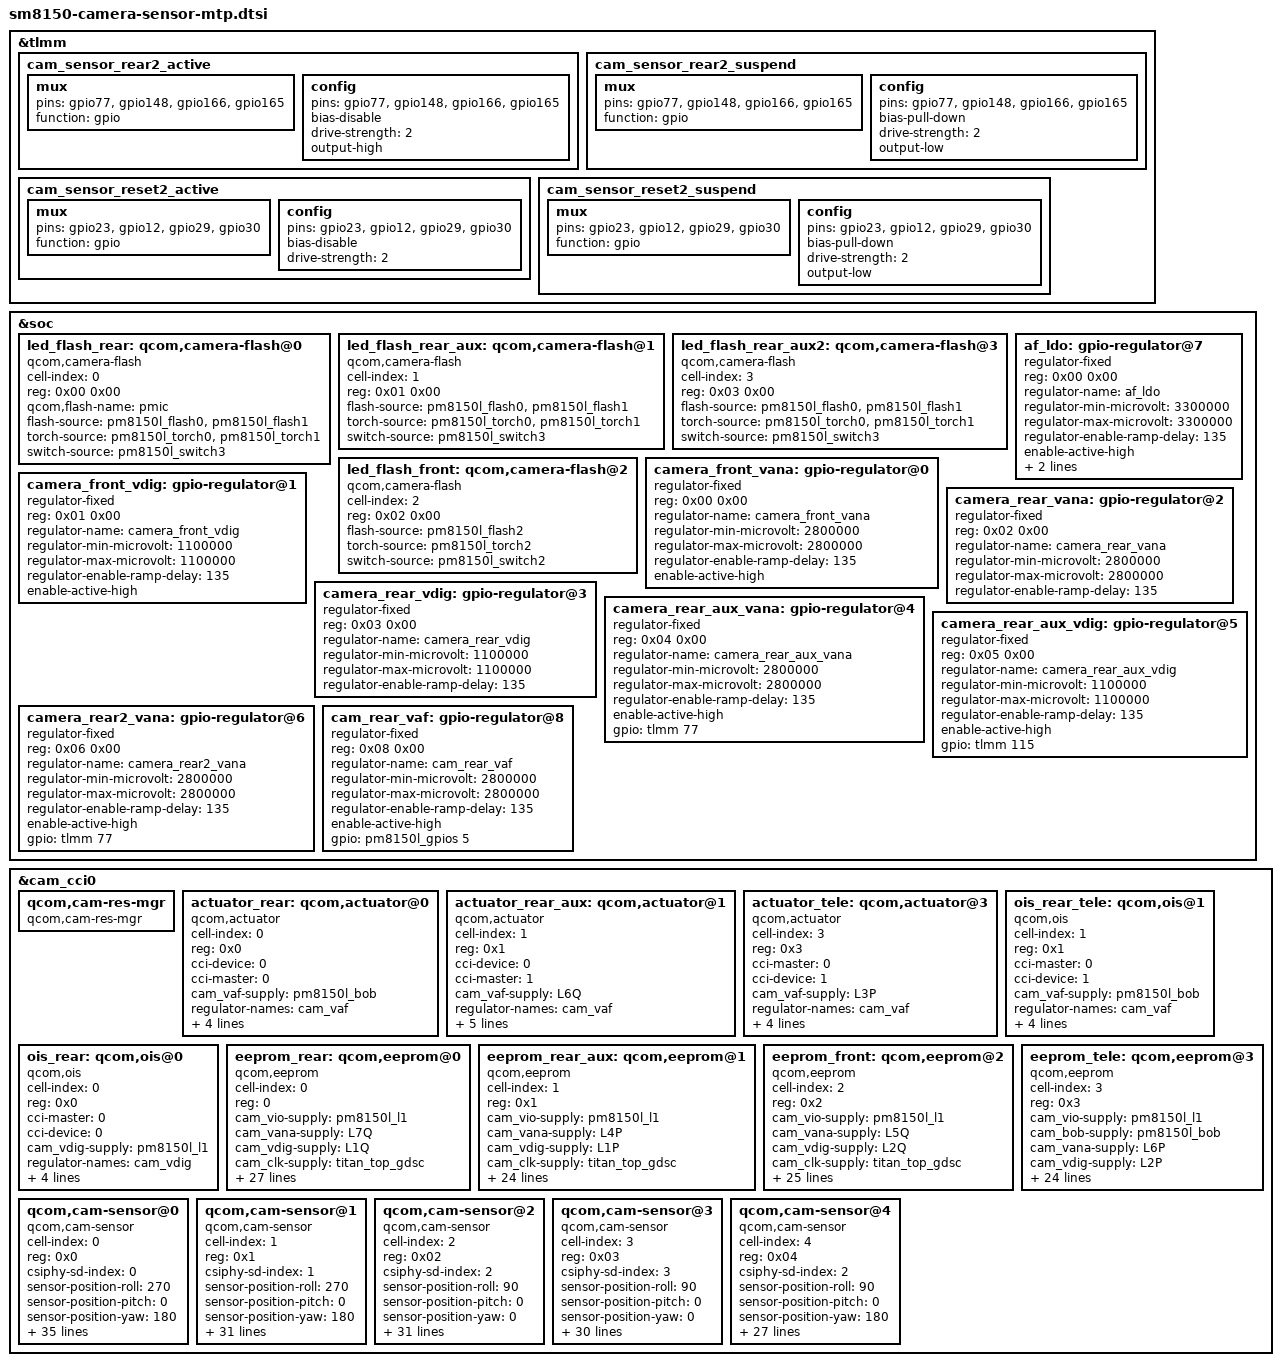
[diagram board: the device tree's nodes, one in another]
/*
 * Copyright (c) 2018-2019, The Linux Foundation. All rights reserved.
 *
 * This program is free software; you can redistribute it and/or modify
 * it under the terms of the GNU General Public License version 2 and
 * only version 2 as published by the Free Software Foundation.
 *
 * This program is distributed in the hope that it will be useful,
 * but WITHOUT ANY WARRANTY; without even the implied warranty of
 * MERCHANTABILITY or FITNESS FOR A PARTICULAR PURPOSE.  See the
 * GNU General Public License for more details.
 */

/* #ifdef VENDOR_EDIT */
&tlmm {
	cam_sensor_rear2_active: cam_sensor_rear2_active {
		/* RESET REAR2 */
		mux {
			pins = "gpio77", "gpio148", "gpio166", "gpio165";
			function = "gpio";
		};

		config {
			pins = "gpio77", "gpio148", "gpio166", "gpio165";
			bias-disable; /* No PULL */
			drive-strength = <2>; /* 2 MA */
			output-high;
		};
	};

	cam_sensor_rear2_suspend: cam_sensor_rear2_suspend {
		/* RESET REAR2 */
		mux {
			pins = "gpio77", "gpio148", "gpio166", "gpio165";
			function = "gpio";
		};

		config {
			pins = "gpio77", "gpio148", "gpio166", "gpio165";
			bias-pull-down; /* PULL DOWN */
			drive-strength = <2>; /* 2 MA */
			output-low;
		};
	};
	cam_sensor_reset2_active: cam_sensor_reset2_active {
		/* RESET REAR2 */
		mux {
			pins = "gpio23","gpio12","gpio29","gpio30";
			function = "gpio";
		};

		config {
			pins = "gpio23","gpio12","gpio29","gpio30";
			bias-disable; /* No PULL */
			drive-strength = <2>; /* 2 MA */
		};
	};

	cam_sensor_reset2_suspend: cam_sensor_reset2_suspend {
		/* RESET REAR2 */
		mux {
			pins = "gpio23","gpio12","gpio29","gpio30";
			function = "gpio";
		};

		config {
			pins = "gpio23","gpio12","gpio29","gpio30";
			bias-pull-down; /* PULL DOWN */
			drive-strength = <2>; /* 2 MA */
			output-low;
		};
	};

};
/* #endif */

&soc {
	#address-cells = <1>;
	#size-cells = <1>;

	led_flash_rear: qcom,camera-flash@0 {
		cell-index = <0>;
		reg = <0x00 0x00>;
		compatible = "qcom,camera-flash";
		qcom,flash-name = "pmic";
		flash-source = <&pm8150l_flash0 &pm8150l_flash1>;
		torch-source = <&pm8150l_torch0 &pm8150l_torch1>;
		switch-source = <&pm8150l_switch3>;
		status = "ok";
	};

	/* #ifdef VENDOR_EDIT */

	led_flash_rear_aux: qcom,camera-flash@1 {
		cell-index = <1>;
		reg = <0x01 0x00>;
		compatible = "qcom,camera-flash";
		flash-source = <&pm8150l_flash0 &pm8150l_flash1>;
		torch-source = <&pm8150l_torch0 &pm8150l_torch1>;
		switch-source = <&pm8150l_switch3>;
		status = "ok";
	};

	led_flash_rear_aux2: qcom,camera-flash@3 {
		cell-index = <3>;
		reg = <0x03 0x00>;
		compatible = "qcom,camera-flash";
		flash-source = <&pm8150l_flash0 &pm8150l_flash1>;
		torch-source = <&pm8150l_torch0 &pm8150l_torch1>;
		switch-source = <&pm8150l_switch3>;
		status = "ok";
	};

	/*#endif*/

	af_ldo: gpio-regulator@7 {
		compatible = "regulator-fixed";
		reg = <0x00 0x00>;
		regulator-name = "af_ldo";
		regulator-min-microvolt = <3300000>;
		regulator-max-microvolt = <3300000>;
		regulator-enable-ramp-delay = <135>;
		enable-active-high;
		gpio = <&tlmm 11 0>;
		pinctrl-names = "default";
		//pinctrl-0 = <&cam_sensor_dvdd_en>;
		vin-supply = <&pm8150l_l1>;
	};

	led_flash_front: qcom,camera-flash@2 {
		cell-index = <2>;
		reg = <0x02 0x00>;
		compatible = "qcom,camera-flash";
		/*#ifndef VENDOR_EDIT*/
		/*
		wled-flash-support;
		flash-source = <&wled_flash>;
		torch-source = <&wled_torch>;
		switch-source = <&wled_switch>;
		*/
		/*#else*/
		flash-source = <&pm8150l_flash2>;
		torch-source = <&pm8150l_torch2>;
		switch-source = <&pm8150l_switch2>;
		/*#endif*/
		status = "ok";
	};

	/* #ifdef VENDOR_EDIT */
	/*
	led_flash_iris: qcom,camera-flash@3 {
		cell-index = <3>;
		reg = <0x03 0x00>;
		compatible = "qcom,camera-flash";
		flash-source = <&pm8150l_flash1>;
		torch-source = <&pm8150l_torch1>;
		switch-source = <&pm8150l_switch0>;
		status = "ok";
	};
	*/
	/*#endif*/

	/*#ifdef VENDOR_EDIT*/
	camera_front_vana: gpio-regulator@0 {
		compatible = "regulator-fixed";
		reg = <0x00 0x00>;
		regulator-name = "camera_front_vana";
		regulator-min-microvolt = <2800000>;
		regulator-max-microvolt = <2800000>;
		regulator-enable-ramp-delay = <135>;
		enable-active-high;
		//gpio = <&pm8150b_gpios 12 0>;
		//pinctrl-names = "default";
		//pinctrl-0 = <&cam_front_vana_default>;
		//vin-supply = <&pm8150l_bob>;
	};

	camera_front_vdig: gpio-regulator@1 {
		compatible = "regulator-fixed";
		reg = <0x01 0x00>;
		regulator-name = "camera_front_vdig";
		regulator-min-microvolt = <1100000>;
		regulator-max-microvolt = <1100000>;
		regulator-enable-ramp-delay = <135>;
		enable-active-high;
		//gpio = <&pm8150b_gpios 10 0>;
		//pinctrl-names = "default";
		//pinctrl-0 = <&cam_front_vdig_default>;
		//vin-supply = <&pm8150l_s8>;
	};

	camera_rear_vana: gpio-regulator@2 {
		compatible = "regulator-fixed";
		reg = <0x02 0x00>;
		regulator-name = "camera_rear_vana";
		regulator-min-microvolt = <2800000>;
		regulator-max-microvolt = <2800000>;
		regulator-enable-ramp-delay = <135>;
		//enable-active-high;
		//gpio = <&pm8150l_gpios 4 0>;
		//pinctrl-names = "default";
		//pinctrl-0 = <&cam_rear_vana_default>;
		//vin-supply = <&pm8150l_bob>;
	};

	camera_rear_vdig: gpio-regulator@3 {
		compatible = "regulator-fixed";
		reg = <0x03 0x00>;
		regulator-name = "camera_rear_vdig";
		regulator-min-microvolt = <1100000>;
		regulator-max-microvolt = <1100000>;
		regulator-enable-ramp-delay = <135>;
		//enable-active-high;
		//gpio = <&pm8150l_gpios 1 0>;
		//pinctrl-names = "default";
		//pinctrl-0 = <&cam_rear_vdig_default>;
		//vin-supply = <&pm8150l_s8>;
	};

	camera_rear_aux_vana: gpio-regulator@4 {
		compatible = "regulator-fixed";
		reg = <0x04 0x00>;
		regulator-name = "camera_rear_aux_vana";
		regulator-min-microvolt = <2800000>;
		regulator-max-microvolt = <2800000>;
		regulator-enable-ramp-delay = <135>;
		enable-active-high;
		gpio = <&tlmm 77 0>;
		//pinctrl-names = "default";
		//pinctrl-0 = <&cam_rear_aux_vana_default>;
		//vin-supply = <&pm8150l_bob>;
	};

	camera_rear_aux_vdig: gpio-regulator@5 {
		compatible = "regulator-fixed";
		reg = <0x05 0x00>;
		regulator-name = "camera_rear_aux_vdig";
		regulator-min-microvolt = <1100000>;
		regulator-max-microvolt = <1100000>;
		regulator-enable-ramp-delay = <135>;
		enable-active-high;
		gpio = <&tlmm 115 0>;
		//pinctrl-names = "default";
		//pinctrl-0 = <&cam_rear_aux_vdig_default>;
		//vin-supply = <&pm8150l_s8>;
	};
	/*#endif*/

        /* #ifdef VENDOR_EDIT */
	camera_rear2_vana: gpio-regulator@6 {
		compatible = "regulator-fixed";
		reg = <0x06 0x00>;
		regulator-name = "camera_rear2_vana";
		regulator-min-microvolt = <2800000>;
		regulator-max-microvolt = <2800000>;
		regulator-enable-ramp-delay = <135>;
		enable-active-high;
		gpio = <&tlmm 77 0>;
		//pinctrl-names = "active", "suspend";
		//pinctrl-0 = <&cam_sensor_rear2_active>;
		//pinctrl-1 = <&cam_sensor_rear2_suspend>;
		//vin-supply = <&pm8150l_bob>;
	};

	cam_rear_vaf: gpio-regulator@8 {
		compatible = "regulator-fixed";
		reg = <0x08 0x00>;
		regulator-name = "cam_rear_vaf";
		regulator-min-microvolt = <2800000>;
		regulator-max-microvolt = <2800000>;
		regulator-enable-ramp-delay = <135>;
		enable-active-high;
		gpio = <&pm8150l_gpios 5 0>;
		//pinctrl-names = "default";
		//pinctrl-0 = <&cam_sensor_dvdd_en>;
		//vin-supply = <&pm8150l_l1>;
	};
	/* #endif */
};

&cam_cci0 {
	#address-cells = <1>;
	#size-cells = <0>;

	qcom,cam-res-mgr {
		compatible = "qcom,cam-res-mgr";
		status = "ok";
	};
	/*
	actuator_rear: qcom,actuator@0 {
		cell-index = <0>;
		reg = <0x0>;
		compatible = "qcom,actuator";
		cci-master = <0>;
		cam_vaf-supply = <&pm8009_s2>;
		regulator-names = "cam_vaf";
		rgltr-cntrl-support;
		rgltr-min-voltage = <2856000>;
		rgltr-max-voltage = <2856000>;
		rgltr-load-current = <0>;
	};

	actuator_rear_aux: qcom,actuator@1 {
		cell-index = <1>;
		reg = <0x1>;
		compatible = "qcom,actuator";
		cci-master = <1>;
		cam_vaf-supply = <&pm8009_s2>;
		regulator-names = "cam_vaf";
		rgltr-cntrl-support;
		rgltr-min-voltage = <2856000>;
		rgltr-max-voltage = <2856000>;
		rgltr-load-current = <0>;
	};

	actuator_front: qcom,actuator@2 {
		cell-index = <2>;
		reg = <0x2>;
		compatible = "qcom,actuator";
		cci-master = <1>;
		cam_vaf-supply = <&pm8009_s2>;
		regulator-names = "cam_vaf";
		rgltr-cntrl-support;
		rgltr-min-voltage = <2856000>;
		rgltr-max-voltage = <2856000>;
		rgltr-load-current = <0>;
	};

	actuator_rear_aux: qcom,actuator@1 {
		cell-index = <1>;
		reg = <0x1>;
		compatible = "qcom,actuator";
		cci-device = <0>;
		cci-master = <0>;
		cam_vaf-supply = <&pm8150l_bob>;
		regulator-names = "cam_vaf";
		rgltr-cntrl-support;
		rgltr-min-voltage = <3300000>;
		rgltr-max-voltage = <3300000>;
		rgltr-load-current = <0>;
		gpio-no-mux = <0>;
		pinctrl-names = "cam_default", "cam_suspend";
		pinctrl-0 = <&cam_sensor_rear_1_vaf_active>;
		pinctrl-1 = <&cam_sensor_rear_1_vaf_suspend>;
		gpios = <&tlmm 35 0>;
		gpio-vaf = <0>;
		gpio-req-tbl-num = <0>;
		gpio-req-tbl-flags = <0>;
		gpio-req-tbl-label = "CAM_VAF_1";
	};
	*/
	actuator_rear: qcom,actuator@0 {
		cell-index = <0>;
		reg = <0x0>;
		compatible = "qcom,actuator";
		cci-device = <0>;
		cci-master = <0>;
		cam_vaf-supply = <&pm8150l_bob>;
		regulator-names = "cam_vaf";
		rgltr-cntrl-support;
		rgltr-min-voltage = <3300000>;
		rgltr-max-voltage = <3300000>;
		rgltr-load-current = <0>;
		/*
		gpio-no-mux = <0>;
		pinctrl-names = "cam_default", "cam_suspend";
		pinctrl-0 = <&cam_rear_vaf_active>;
		pinctrl-1 = <&cam_rear_vaf_suspend>;
		gpios = <&pm8150l_gpios 5 0>;
		gpio-vaf = <0>;
		gpio-req-tbl-num = <0>;
		gpio-req-tbl-flags = <0>;
		gpio-req-tbl-label = "CAM_VAF_0";
		*/
	};

	actuator_rear_aux: qcom,actuator@1 {
		cell-index = <1>;
		reg = <0x1>;
		compatible = "qcom,actuator";
		cci-device = <0>;
		cci-master = <1>;
		cam_vaf-supply = <&L6Q>;
		regulator-names = "cam_vaf";
		rgltr-cntrl-support;
		rgltr-min-voltage = <2800000>;
		rgltr-max-voltage = <2800000>;
		rgltr-load-current = <0>;
		gpio-no-mux = <0>;
		//pinctrl-names = "cam_default", "cam_suspend";
		//pinctrl-0 = <&cam_sensor_rear_1_vaf_active>;
		//pinctrl-1 = <&cam_sensor_rear_1_vaf_suspend>;
		/* #ifdef VENDOR_EDIT */
		//gpios = <&tlmm 11 0>;
		//gpio-vaf = <0>;
		//gpio-req-tbl-num = <0>;
		//gpio-req-tbl-flags = <0>;
		//gpio-req-tbl-label = "CAM_VAF_1";
		/* #endif */
	};

	/* #ifdef VENDOR_EDIT */
	actuator_tele: qcom,actuator@3 {
		cell-index = <3>;
		reg = <0x3>;
		compatible = "qcom,actuator";
		cci-master = <0>;
		cci-device = <1>;
		cam_vaf-supply = <&L3P>;
		regulator-names = "cam_vaf";
		rgltr-cntrl-support;
		rgltr-min-voltage = <2800000>;
		rgltr-max-voltage = <2800000>;
		rgltr-load-current = <0>;
		status = "ok";
	};

	ois_rear_tele: qcom,ois@1 {
		cell-index = <1>;
		reg = <0x1>;
		compatible = "qcom,ois";
		cci-master = <0>;
		cci-device = <1>;
		cam_vaf-supply = <&pm8150l_bob>;
		regulator-names = "cam_vaf";
		rgltr-cntrl-support;
		rgltr-min-voltage = <3300000>;
		rgltr-max-voltage = <3300000>;
		rgltr-load-current = <0>;
		status = "ok";
	};
	/* #endif */

	ois_rear: qcom,ois@0 {
		cell-index = <0>;
		reg = <0x0>;
		compatible = "qcom,ois";
		cci-master = <0>;
		cci-device = <0>;
		cam_vdig-supply = <&pm8150l_l1>;
		regulator-names = "cam_vdig";
		rgltr-cntrl-support;
		rgltr-min-voltage = <1800000>;
		rgltr-max-voltage = <1800000>;
		rgltr-load-current = <0>;
		status = "ok";
	};

	/*#ifdef VENDOR_EDIT*/
	/*remark by hongbo.dai@camera*/
	eeprom_rear: qcom,eeprom@0 {
		cell-index = <0>;
		reg = <0>;
		compatible = "qcom,eeprom";
		cam_vio-supply = <&pm8150l_l1>;
		//cam_bob-supply = <&pm8150l_bob>;
		cam_vana-supply = <&L7Q>;
		cam_vdig-supply = <&L1Q>;
		cam_clk-supply = <&titan_top_gdsc>;
		cam_vaf-supply = <&L3Q>;
		cam_v_custom1-supply = <&L4Q>;
		regulator-names = "cam_vio", "cam_vana", "cam_vdig",
			"cam_clk", "cam_vaf","cam_v_custom1";
		rgltr-cntrl-support;
		pwm-switch;
		rgltr-min-voltage = <0 2900000 1100000 0 2800000 1800000>;
		rgltr-max-voltage = <0 2900000 1100000 0 2800000 1800000>;
		rgltr-load-current = <0 80000 800000 0 80000 300000>;
		gpio-no-mux = <0>;
		pinctrl-names = "cam_default", "cam_suspend";
		pinctrl-0 = <&cam_sensor_mclk0_active
				&cam_rear_reset_active>;
		pinctrl-1 = <&cam_sensor_mclk0_suspend
				&cam_rear_reset_suspend>;
		gpios = <&tlmm 13 0>,
			<&pm8150_gpios 1 0>;
		gpio-reset = <1>;
		gpio-req-tbl-num = <0 1>;
		gpio-req-tbl-flags = <1 0>;
		gpio-req-tbl-label = "CAMIF_MCLK3",
					"CAM_RESET0";
		sensor-mode = <0>;
		cci-master = <0>;
		status = "ok";
		clocks = <&clock_camcc CAM_CC_MCLK0_CLK>;
		clock-names = "cam_clk";
		clock-cntl-level = "turbo";
		clock-rates = <19200000>;
	};

	eeprom_rear_aux: qcom,eeprom@1 {
		cell-index = <1>;
		reg = <0x1>;
		compatible = "qcom,eeprom";
		cam_vio-supply = <&pm8150l_l1>;
		cam_vana-supply = <&L4P>;
		cam_vdig-supply = <&L1P>;
		cam_clk-supply = <&titan_top_gdsc>;
		cam_bob-supply = <&pm8150l_bob>;
		regulator-names = "cam_vio", "cam_vana", "cam_vdig",
			"cam_clk", "cam_bob";
		rgltr-cntrl-support;
		pwm-switch;
		rgltr-min-voltage = <0 2800000 1100000 0 3008000>;
		rgltr-max-voltage = <0 2800000 1100000 0 4000000>;
		rgltr-load-current = <0 80000 60000 0 2000000>;
		gpio-no-mux = <0>;
		pinctrl-names = "cam_default", "cam_suspend";
		pinctrl-0 = <&cam_sensor_mclk1_active
				 &cam_sensor_active_rear_aux>;
		pinctrl-1 = <&cam_sensor_mclk1_suspend
				 &cam_sensor_suspend_rear_aux>;
		gpios = <&tlmm 14 0>,
			<&tlmm 30 0>;
		gpio-reset = <1>;
		gpio-req-tbl-num = <0 1>;
		gpio-req-tbl-flags = <1 0>;
		gpio-req-tbl-label = "CAMIF_MCLK1",
					"CAM_RESET1";
		sensor-mode = <0>;
		cci-device = <0>;
		cci-master = <1>;
		status = "ok";
		clocks = <&clock_camcc CAM_CC_MCLK1_CLK>;
		clock-names = "cam_clk";
		clock-cntl-level = "turbo";
		clock-rates = <19200000>;
	};

	/* #ifdef VENDOR_EDIT */
	eeprom_front: qcom,eeprom@2 {
		cell-index = <2>;
		reg = <0x2>;
		compatible = "qcom,eeprom";
		cam_vio-supply = <&pm8150l_l1>;
		cam_vana-supply = <&L5Q>;
		cam_vdig-supply = <&L2Q>;
		cam_clk-supply = <&titan_top_gdsc>;
		regulator-names = "cam_vio", "cam_vana", "cam_vdig", "cam_clk";
		rgltr-cntrl-support;
		pwm-switch;
		rgltr-min-voltage = <1800000 2800000 1050000 0 >;
		rgltr-max-voltage = <1800000 2800000 1050000 0 >;
		rgltr-load-current = <80000 50000 50000 0 >;
		gpio-no-mux = <0>;
		pinctrl-names = "cam_default", "cam_suspend","cam_reset";
		pinctrl-0 = <&cam_sensor_mclk2_active
					&cam_sensor_reset2_active>;
		pinctrl-1 = <&cam_sensor_mclk2_suspend
					&cam_sensor_reset2_suspend>;
		gpios = <&tlmm 15 0>,
				<&tlmm 12 0>,
				<&tlmm 29 0>;
		gpio-reset = <1>;
		gpio-custom1 = <2>;
		gpio-req-tbl-num = <0 1 2>;
		gpio-req-tbl-flags = <1 0 0>;
		gpio-req-tbl-label = "CAMIF_MCLK_2",
								"CAM_RESET2",
								"CAM_FRONT_EN";
		sensor-mode = <0>;
		cci-device = <1>;
		cci-master = <1>;
		status = "ok";
		clocks = <&clock_camcc CAM_CC_MCLK2_CLK>;
		clock-names = "cam_clk";
		clock-cntl-level = "turbo";
		clock-rates = <24000000>;
	};

	eeprom_tele: qcom,eeprom@3 {
		cell-index = <3>;
		reg = <0x3>;
		compatible = "qcom,eeprom";
		cam_vio-supply = <&pm8150l_l1>;
		cam_bob-supply = <&pm8150l_bob>;
		cam_vana-supply = <&L6P>;
		cam_vdig-supply = <&L2P>;
		cam_clk-supply = <&titan_top_gdsc>;
		regulator-names = "cam_vio", "cam_vana", "cam_clk", "cam_bob","cam_vdig";
		rgltr-cntrl-support;
		pwm-switch;
		rgltr-min-voltage = <0 2800000 0 3008000 1050000>;
		rgltr-max-voltage = <0 2800000 0 4000000 1050000>;
		rgltr-load-current = <0 80000 0 2000000 80000>;
		gpio-no-mux = <0>;
		pinctrl-names = "cam_default", "cam_suspend","cam_reset";
		pinctrl-0 = <&cam_sensor_mclk3_active
				 &cam_rear_aux2_reset_active>;
		pinctrl-1 = <&cam_sensor_mclk3_suspend
				 &cam_rear_aux2_reset_suspend>;
		gpios = <&tlmm 16 0>,
			<&tlmm 23 0>;
		gpio-reset = <1>;
		gpio-req-tbl-num = <0 1>;
		gpio-req-tbl-flags = <1 0>;
		gpio-req-tbl-label = "CAMIF_MCLK3",
					"CAM_RESET_3";
		sensor-mode = <0>;
		cci-device = <1>;
		cci-master = <0>;
		status = "ok";
		clocks = <&clock_camcc CAM_CC_MCLK3_CLK>;
		clock-names = "cam_clk";
		clock-cntl-level = "turbo";
		clock-rates = <19200000>;
	};
	/* #endif */

/*
	eeprom_front: qcom,eeprom@2 {
		cell-index = <2>;
		reg = <0x2>;
		compatible = "qcom,eeprom";
		cam_vio-supply = <&pm8150l_l1>;
		cam_vana-supply = <&pm8009_l6>;
		cam_vdig-supply = <&pm8009_l2>;
		cam_clk-supply = <&titan_top_gdsc>;
		cam_vaf-supply = <&pm8009_s2>;
		regulator-names = "cam_vio", "cam_vana", "cam_vdig",
			"cam_clk", "cam_vaf";
		rgltr-cntrl-support;
		rgltr-min-voltage = <0 2856000 1200000 0 2856000>;
		rgltr-max-voltage = <0 2856000 1200000 0 2856000>;
		rgltr-load-current = <0 80000 1200000 0 0>;
		gpio-no-mux = <0>;
		pinctrl-names = "cam_default", "cam_suspend";
		pinctrl-0 = <&cam_sensor_mclk2_active
				 &cam_sensor_active_front>;
		pinctrl-1 = <&cam_sensor_mclk2_suspend
				 &cam_sensor_suspend_front>;
		gpios = <&tlmm 15 0>,
			<&tlmm 12 0>;
		gpio-reset = <1>;
		gpio-req-tbl-num = <0 1>;
		gpio-req-tbl-flags = <1 0>;
		gpio-req-tbl-label = "CAMIF_MCLK2",
					"CAM_RESET2";
		sensor-position = <1>;
		sensor-mode = <0>;
		cci-master = <1>;
		status = "ok";
		clocks = <&clock_camcc CAM_CC_MCLK2_CLK>;
		clock-names = "cam_clk";
		clock-cntl-level = "turbo";
		clock-rates = <24000000>;
	};

	qcom,cam-sensor@0 {
		cell-index = <0>;
		compatible = "qcom,cam-sensor";
		reg = <0x0>;
		csiphy-sd-index = <0>;
		sensor-position-roll = <90>;
		sensor-position-pitch = <0>;
		sensor-position-yaw = <180>;
		led-flash-src = <&led_flash_rear>;
		actuator-src = <&actuator_rear>;
		ois-src = <&ois_rear>;
		eeprom-src = <&eeprom_rear>;
		cam_vio-supply = <&pm8150l_l1>;
		cam_bob-supply = <&pm8150l_bob>;
		cam_vana-supply = <&pm8009_l5>;
		cam_vdig-supply = <&pm8009_l2>;
		cam_clk-supply = <&titan_top_gdsc>;
		regulator-names = "cam_vio", "cam_vana", "cam_vdig",
			"cam_clk", "cam_bob";
		rgltr-cntrl-support;
		pwm-switch;
		rgltr-min-voltage = <0 2800000 1200000 0 3008000>;
		rgltr-max-voltage = <0 2800000 1200000 0 4000000>;
		rgltr-load-current = <0 80000 1200000 0 2000000>;
		gpio-no-mux = <0>;
		pinctrl-names = "cam_default", "cam_suspend";
		pinctrl-0 = <&cam_sensor_mclk0_active
				&cam_sensor_active_rear>;
		pinctrl-1 = <&cam_sensor_mclk0_suspend
				&cam_sensor_suspend_rear>;
		gpios = <&tlmm 13 0>,
			<&tlmm 78 0>;
		gpio-reset = <1>;
		gpio-req-tbl-num = <0 1>;
		gpio-req-tbl-flags = <1 0>;
		gpio-req-tbl-label = "CAMIF_MCLK0",
					"CAM_RESET0";
		sensor-mode = <0>;
		cci-master = <0>;
		status = "ok";
		clocks = <&clock_camcc CAM_CC_MCLK0_CLK>;
		clock-names = "cam_clk";
		clock-cntl-level = "turbo";
		clock-rates = <24000000>;
	};
	*/

	qcom,cam-sensor@0 {
		cell-index = <0>;
		compatible = "qcom,cam-sensor";
		reg = <0x0>;
		csiphy-sd-index = <0>;
		sensor-position-roll = <270>;
		sensor-position-pitch = <0>;
		sensor-position-yaw = <180>;
		led-flash-src = <&led_flash_rear>;
		actuator-src = <&actuator_rear>;
		ois-src = <&ois_rear>;
		eeprom-src = <&eeprom_rear>;
		cam_vio-supply = <&pm8150l_l1>;
		//cam_bob-supply = <&pm8150l_bob>;
		cam_vana-supply = <&L7Q>;
		cam_vdig-supply = <&L1Q>;
		cam_clk-supply = <&titan_top_gdsc>;
		cam_vaf-supply = <&L3Q>;
		cam_v_custom1-supply = <&L4Q>;
		regulator-names = "cam_vio", "cam_vana", "cam_vdig",
			"cam_clk", "cam_vaf","cam_v_custom1";
		rgltr-cntrl-support;
		pwm-switch;
		rgltr-min-voltage = <0 2900000 1100000 0 2800000 1800000>;
		rgltr-max-voltage = <0 2900000 1100000 0 2800000 1800000>;
		rgltr-load-current = <0 80000 800000 0 80000 300000>;
		gpio-no-mux = <0>;
		pinctrl-names = "cam_default", "cam_suspend";
		pinctrl-0 = <&cam_sensor_mclk0_active
				&cam_rear_reset_active>;
		pinctrl-1 = <&cam_sensor_mclk0_suspend
				&cam_rear_reset_suspend>;
		gpios = <&tlmm 13 0>,
			<&pm8150_gpios 1 0>;
		gpio-reset = <1>;
		gpio-req-tbl-num = <0 1>;
		gpio-req-tbl-flags = <1 0>;
		gpio-req-tbl-label = "CAMIF_MCLK3",
					"CAM_RESET0";
		sensor-mode = <0>;
		cci-master = <0>;
		status = "ok";
		clocks = <&clock_camcc CAM_CC_MCLK0_CLK>;
		clock-names = "cam_clk";
		clock-cntl-level = "turbo";
		clock-rates = <19200000>;
	};

	qcom,cam-sensor@1 {
		cell-index = <1>;
		compatible = "qcom,cam-sensor";
		reg = <0x1>;
		csiphy-sd-index = <1>;
		sensor-position-roll = <270>;
		sensor-position-pitch = <0>;
		sensor-position-yaw = <180>;
		actuator-src = <&actuator_rear_aux>;
		led-flash-src = <&led_flash_rear_aux>;
		eeprom-src = <&eeprom_rear_aux>;
		cam_vio-supply = <&pm8150l_l1>;
		cam_vana-supply = <&L4P>;
		cam_vdig-supply = <&L1P>;
		cam_clk-supply = <&titan_top_gdsc>;
		cam_bob-supply = <&pm8150l_bob>;
		regulator-names = "cam_vio", "cam_vana", "cam_vdig",
			"cam_clk", "cam_bob";
		rgltr-cntrl-support;
		pwm-switch;
		rgltr-min-voltage = <0 2800000 1100000 0 3008000>;
		rgltr-max-voltage = <0 2800000 1100000 0 4000000>;
		rgltr-load-current = <0 80000 60000 0 2000000>;
		gpio-no-mux = <0>;
		pinctrl-names = "cam_default", "cam_suspend";
		pinctrl-0 = <&cam_sensor_mclk1_active
				&cam_sensor_active_rear_aux>;
		pinctrl-1 = <&cam_sensor_mclk1_suspend
				&cam_sensor_suspend_rear_aux>;
		gpios = <&tlmm 14 0>,
			<&tlmm 30 0>;
		gpio-reset = <1>;
		gpio-req-tbl-num = <0 1>;
		gpio-req-tbl-flags = <1 0>;
		gpio-req-tbl-label = "CAMIF_MCLK1",
					"CAM_RESET1";
		sensor-mode = <0>;
		cci-device = <0>;
		cci-master = <1>;
		status = "ok";
		clocks = <&clock_camcc CAM_CC_MCLK1_CLK>;
		clock-names = "cam_clk";
		clock-cntl-level = "turbo";
		clock-rates = <19200000>;
	};

	/*#ifndef VENDOR_EDIT*/
	/*
	qcom,cam-sensor@2 {
		cell-index = <2>;
		compatible = "qcom,cam-sensor";
		reg = <0x02>;
		csiphy-sd-index = <2>;
		sensor-position-roll = <90>;
		sensor-position-pitch = <0>;
		sensor-position-yaw = <0>;
		eeprom-src = <&eeprom_front>;
		actuator-src = <&actuator_front>;
		led-flash-src = <&led_flash_front>;
		cam_vio-supply = <&pm8150l_l1>;
		cam_bob-supply = <&pm8150l_bob>;
		cam_vana-supply = <&pm8009_l6>;
		cam_vdig-supply = <&pm8009_l2>;
		cam_clk-supply = <&titan_top_gdsc>;
		regulator-names = "cam_vio", "cam_vana", "cam_vdig",
			"cam_clk", "cam_bob";
		rgltr-cntrl-support;
		pwm-switch;
		rgltr-min-voltage = <0 2856000 1200000 0 3008000>;
		rgltr-max-voltage = <0 2856000 1200000 0 4000000>;
		rgltr-load-current = <0 80000 1200000 0 2000000>;
		gpio-no-mux = <0>;
		pinctrl-names = "cam_default", "cam_suspend";
		pinctrl-0 = <&cam_sensor_mclk2_active
				 &cam_sensor_active_front>;
		pinctrl-1 = <&cam_sensor_mclk2_suspend
				 &cam_sensor_suspend_front>;
		gpios = <&tlmm 15 0>,
			<&tlmm 12 0>;
		gpio-reset = <1>;
		gpio-req-tbl-num = <0 1>;
		gpio-req-tbl-flags = <1 0>;
		gpio-req-tbl-label = "CAMIF_MCLK2",
					"CAM_RESET2";
		sensor-mode = <0>;
		cci-master = <1>;
		status = "ok";
		clocks = <&clock_camcc CAM_CC_MCLK2_CLK>;
		clock-names = "cam_clk";
		clock-cntl-level = "turbo";
		clock-rates = <24000000>;
	};
	*/
	/*#else*/
	qcom,cam-sensor@2 {
		cell-index = <2>;
		compatible = "qcom,cam-sensor";
		reg = <0x02>;
		csiphy-sd-index = <2>;
		sensor-position-roll = <90>;
		sensor-position-pitch = <0>;
		sensor-position-yaw = <0>;
		eeprom-src = <&eeprom_front>;
		//actuator-src = <&actuator_front>;
		led-flash-src = <&led_flash_front>;
		cam_vio-supply = <&pm8150l_l1>;
		cam_vana-supply = <&L5Q>;
		cam_vdig-supply = <&L2Q>;
		cam_clk-supply = <&titan_top_gdsc>;
		regulator-names = "cam_vio", "cam_vana", "cam_vdig", "cam_clk";
		rgltr-cntrl-support;
		pwm-switch;
		rgltr-min-voltage = <1800000 2800000 1050000 0 >;
		rgltr-max-voltage = <1800000 2800000 1050000 0 >;
		rgltr-load-current = <80000 50000 50000 0 >;
		gpio-no-mux = <0>;
		pinctrl-names = "cam_default", "cam_suspend","cam_reset";
		pinctrl-0 = <&cam_sensor_mclk2_active
					&cam_sensor_reset2_active>;
		pinctrl-1 = <&cam_sensor_mclk2_suspend
					&cam_sensor_reset2_suspend>;
		gpios = <&tlmm 15 0>,
				<&tlmm 12 0>,
				<&tlmm 29 0>;
		gpio-reset = <1>;
		gpio-custom1 = <2>;
		gpio-req-tbl-num = <0 1 2>;
		gpio-req-tbl-flags = <1 0 0>;
		gpio-req-tbl-label = "CAMIF_MCLK_2",
								"CAM_RESET2",
								"CAM_FRONT_EN";
                sensor-mode = <0>;
		cci-device = <1>;
		cci-master = <1>;
		status = "ok";
		clocks = <&clock_camcc CAM_CC_MCLK2_CLK>;
		clock-names = "cam_clk";
		clock-cntl-level = "turbo";
		clock-rates = <24000000>;
	};
	/*#endif*/

	/* #ifndef VENDOR_EDIT */
	/*
	qcom,cam-sensor@3 {
		cell-index = <3>;
		compatible = "qcom,cam-sensor";
		reg = <0x03>;
		csiphy-sd-index = <3>;
		sensor-position-roll = <270>;
		sensor-position-pitch = <0>;
		sensor-position-yaw = <0>;
		led-flash-src = <&led_flash_iris>;
		cam_vio-supply = <&pm8150l_l1>;
		cam_bob-supply = <&pm8150l_bob>;
		cam_vana-supply = <&pm8009_l5>;
		cam_vdig-supply = <&pm8009_l2>;
		cam_clk-supply = <&titan_top_gdsc>;
		regulator-names = "cam_vio", "cam_vana", "cam_vdig",
			"cam_clk", "cam_bob";
		rgltr-cntrl-support;
		pwm-switch;
		rgltr-min-voltage = <0 2800000 1200000 0 3008000>;
		rgltr-max-voltage = <0 2800000 1200000 0 4000000>;
		rgltr-load-current = <0 80000 1200000 0 2000000>;
		gpio-no-mux = <0>;
		pinctrl-names = "cam_default", "cam_suspend";
		pinctrl-0 = <&cam_sensor_mclk3_active
				 &cam_sensor_active_iris>;
		pinctrl-1 = <&cam_sensor_mclk3_suspend
				 &cam_sensor_suspend_iris>;
		gpios = <&tlmm 16 0>,
			<&tlmm 23 0>,
			<&tlmm 26 0>;
		gpio-reset = <1>;
		gpio-req-tbl-num = <0 1 2>;
		gpio-req-tbl-flags = <1 0 0>;
		gpio-req-tbl-label = "CAMIF_MCLK3",
					"CAM_RESET3",
					"IMG_START";
		sensor-mode = <0>;
		cci-device = <1>;
		cci-master = <1>;
		status = "ok";
		clocks = <&clock_camcc CAM_CC_MCLK3_CLK>;
		clock-names = "cam_clk";
		clock-cntl-level = "turbo";
		clock-rates = <24000000>;
	};
	*/
	/* #else */

	qcom,cam-sensor@3 {
		cell-index = <3>;
		compatible = "qcom,cam-sensor";
		reg = <0x03>;
		csiphy-sd-index = <3>;
		sensor-position-roll = <90>;
		sensor-position-pitch = <0>;
		sensor-position-yaw = <0>;
		eeprom-src = <&eeprom_tele>;
		//led-flash-src = <&led_flash_rear_aux2>;
		actuator-src = <&actuator_tele>;
		//ois-src = <&ois_rear_tele>;
		cam_vio-supply = <&pm8150l_l1>;
		cam_bob-supply = <&pm8150l_bob>;
		cam_vana-supply = <&L6P>;
		cam_vdig-supply = <&L2P>;
		cam_clk-supply = <&titan_top_gdsc>;
		regulator-names = "cam_vio", "cam_vana", "cam_clk", "cam_bob","cam_vdig";
		rgltr-cntrl-support;
		pwm-switch;
		rgltr-min-voltage = <0 2800000 0 3008000 1050000>;
		rgltr-max-voltage = <0 2800000 0 4000000 1050000>;
		rgltr-load-current = <0 80000 0 2000000 80000>;
		gpio-no-mux = <0>;
		pinctrl-names = "cam_default", "cam_suspend","cam_reset";
		pinctrl-0 = <&cam_sensor_mclk3_active
				 &cam_rear_aux2_reset_active>;
		pinctrl-1 = <&cam_sensor_mclk3_suspend
				 &cam_rear_aux2_reset_suspend>;
		gpios = <&tlmm 16 0>,
			<&tlmm 23 0>;
		gpio-reset = <1>;
		gpio-req-tbl-num = <0 1>;
		gpio-req-tbl-flags = <1 0>;
		gpio-req-tbl-label = "CAMIF_MCLK3",
					"CAM_RESET_3";
		sensor-mode = <0>;
		cci-device = <1>;
		cci-master = <0>;
		status = "ok";
		clocks = <&clock_camcc CAM_CC_MCLK3_CLK>;
		clock-names = "cam_clk";
		clock-cntl-level = "turbo";
		clock-rates = <19200000>;
	};
	/* #endif */
	qcom,cam-sensor@4 {
		cell-index = <4>;
		compatible = "qcom,cam-sensor";
		reg = <0x04>;
		csiphy-sd-index = <2>;
		sensor-position-roll = <90>;
		sensor-position-pitch = <0>;
		sensor-position-yaw = <180>;
		//eeprom-src = <&eeprom_front>;
		//actuator-src = <&actuator_front>;
		//led-flash-src = <&led_flash_front>;
		cam_vio-supply = <&pm8150l_l1>;
		cam_vana-supply = <&L5P>;
		cam_clk-supply = <&titan_top_gdsc>;
		regulator-names = "cam_vio", "cam_vana", "cam_clk";
		rgltr-cntrl-support;
		pwm-switch;
		rgltr-min-voltage = <1800000 2800000 0 >;
		rgltr-max-voltage = <1800000 2800000 0 >;
		rgltr-load-current = <80000 50000 0 >;
		gpio-no-mux = <0>;
		pinctrl-names = "cam_default", "cam_suspend","cam_reset";
		pinctrl-0 = <&cam_sensor_mclk2_active
					&cam_sensor_reset2_active>;
		pinctrl-1 = <&cam_sensor_mclk2_suspend
					&cam_sensor_reset2_suspend>;
		gpios = <&tlmm 15 0>,
				<&tlmm 12 0>,
				<&tlmm 29 0>;
		gpio-reset = <1>;
		gpio-custom1 = <2>;
		gpio-req-tbl-num = <0 1 2>;
		gpio-req-tbl-flags = <1 0 0>;
		gpio-req-tbl-label = "CAMIF_MCLK_4",
								"CAM_RESET4",
								"CAM_MONO_EN";
		sensor-mode = <0>;
		cci-device = <1>;
		cci-master = <0>;
		status = "ok";
		clocks = <&clock_camcc CAM_CC_MCLK2_CLK>;
		clock-names = "cam_clk";
		clock-cntl-level = "turbo";
		clock-rates = <24000000>;
	};
};
